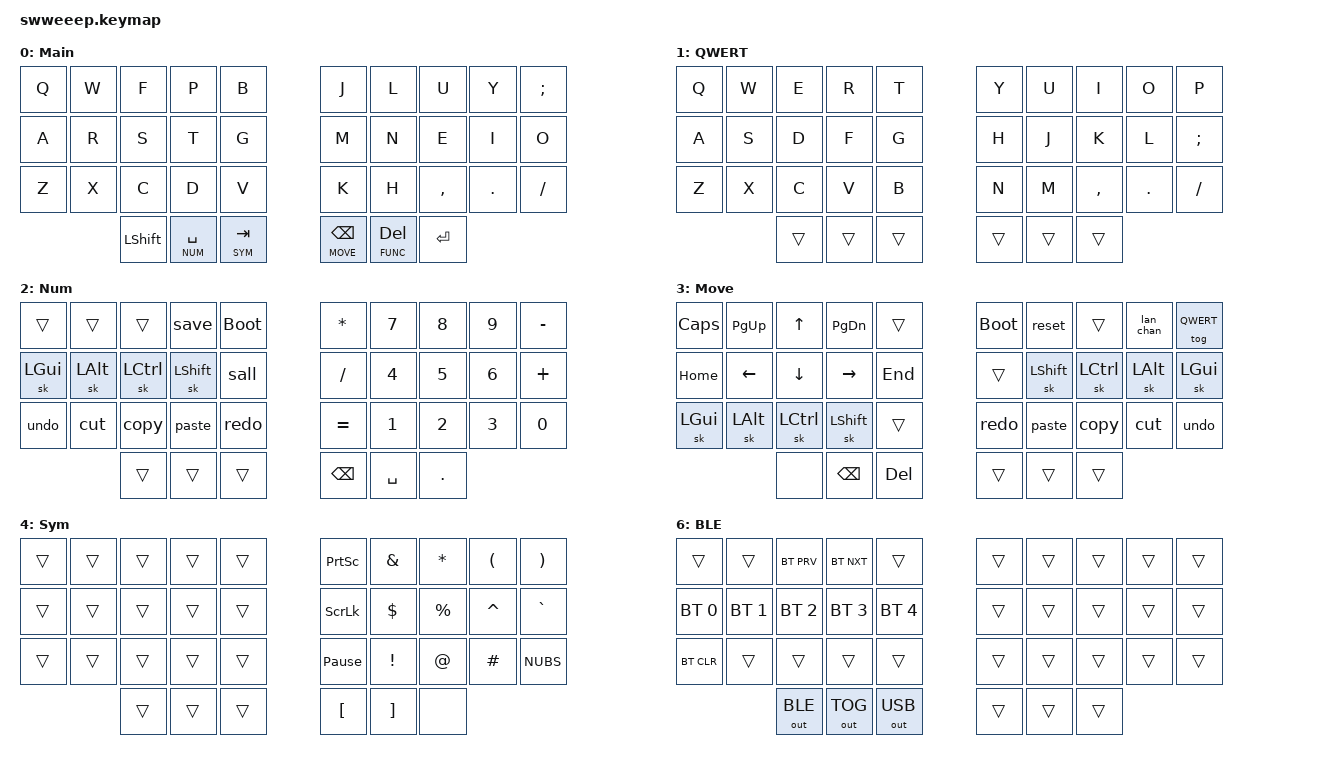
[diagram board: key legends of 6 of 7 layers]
#include <behaviors.dtsi>
#include <dt-bindings/zmk/keys.h>
#include <dt-bindings/zmk/bt.h>
#include <dt-bindings/zmk/outputs.h>

#define MAIN  0
#define QWERT 1
#define NUM   2
#define MOVE  3
#define SYM   4
#define FUNC  5
#define BLE   6

&caps_word {
    continue-list = <UNDERSCORE MINUS>;
};

/ {
    combos {
        compatible = "zmk,combos";
        combo_undo {
            timeout-ms = <50>;
            key-positions = <20 21>;
            bindings = <&kp LC(Z)>;
        };
        combo_q {
            timeout-ms = <50>;
            key-positions = <21 22>;
            bindings = <&kp Q>;
        };
        combo_semicolon {
            timeout-ms = <50>;
            key-positions = <27 28>;
            bindings = <&kp SEMI>;
        };
    };
};

/ {

    behaviors {
        hm: homerow_mods {
            compatible = "zmk,behavior-hold-tap";
            label = "HOMEROW_MODS";
            #binding-cells = <2>;
            tapping-term-ms = <200>;
            quick_tap_ms = <0>;
            flavor = "balanced";
            bindings = <&kp>, <&kp>;
        };
        hs: homerow_shift {
            compatible = "zmk,behavior-hold-tap";
            label = "HOMEROW_SHIFT";
            #binding-cells = <2>;
            tapping-term-ms = <175>;
            quick_tap_ms = <0>;
            flavor = "balanced";
            bindings = <&kp>, <&kp>;
        };
    };

    keymap {
        compatible = "zmk,keymap";

        main_layer {
            label = "Main";

            bindings = <
    &kp Q        &kp W        &kp F       &kp P         &kp B                                       &kp J         &kp L        &kp U         &kp Y       &kp SEMI
    &kp A        &kp R        &kp S       &kp T         &kp G                                       &kp M         &kp N        &kp E         &kp I       &kp O
    &kp Z        &kp X        &kp C       &kp D         &kp V                                       &kp K         &kp H        &kp COMMA     &kp DOT     &kp FSLH
                              &kp LSHFT   &lt NUM SPACE &lt SYM TAB                             &lt MOVE BSPC   &lt FUNC DEL  &kp RET
            >;
        };

        qwert_layer {
            label = "QWERT";

            bindings = <
    &kp Q        &kp W        &kp E       &kp R         &kp T                                   &kp Y         &kp U        &kp I         &kp O       &kp P
    &kp A        &kp S        &kp D       &kp F         &kp G                                   &kp H         &kp J        &kp K         &kp L       &kp SEMI
    &kp Z        &kp X        &kp C       &kp V         &kp B                                   &kp N         &kp M        &kp COMMA     &kp DOT     &kp FSLH
                              &trans      &trans        &trans                                  &trans        &trans       &trans
            >;
        };

        num_layer {
            label = "Num";

            bindings = <
    &trans       &trans       &trans      &save         &bootloader                             &kp ASTRK     &kp N7       &kp N8        &kp N9      &kp MINUS
    &sk LGUI     &sk LALT     &sk LCTRL   &sk LSHFT     &sall                                   &kp FSLH      &kp N4       &kp N5        &kp N6      &kp PLUS
    &undo        &cut         &copy       &paste        &redo                                   &kp EQUAL     &kp N1       &kp N2        &kp N3      &kp N0
                              &trans        &trans      &trans                                  &kp BSPC      &kp SPACE    &kp DOT
            >;
        };

        move_layer {
            label = "Move";

            bindings = <
    &kp CAPS     &kp PG_UP    &kp UP      &kp PG_DN     &trans                                   &bootloader   &reset       &trans        &lan_chan   &tog QWERT
    &kp HOME     &kp LEFT     &kp DOWN    &kp RIGHT     &kp END                                  &trans        &sk LSHIFT   &sk LCTRL     &sk LALT    &sk LGUI
    &sk LGUI     &sk LALT     &sk LCTRL    &sk LSHFT     &trans                                  &redo         &paste       &copy         &cut        &undo
                              &none       &kp BSPC      &kp DEL                                  &trans        &trans       &trans
            >;
        };

        sym_layer {
            label = "Sym";

            bindings = <
    &trans      &trans      &trans      &trans      &trans                                       &kp PSCRN   &kp AMPS    &kp ASTRK   &kp LPAR    &kp RPAR
    &trans      &trans      &trans      &trans      &trans                                       &kp SLCK    &kp DLLR    &kp PRCNT   &kp CARET   &kp GRAVE
    &trans      &trans      &trans      &trans      &trans                                 &kp PAUSE_BREAK   &kp EXCL    &kp AT      &kp HASH    &kp NUBS
                            &trans      &trans      &trans                                       &kp LBKT    &kp RBKT    &none
            >;
        };

        func_layer {
            label = "Func";

            bindings = <
    &kp F9     &kp F10    &kp F11   &kp F12    &kp K_VOL_UP                                      &trans   &kp LANG1    &trans        &trans      &trans
    &kp F5     &kp F6     &kp F7    &kp F8     &kp C_MUTE                                        &trans   &sk LSHF T   &sk LCTRL     &sk LALT    &sk LGUI
    &sk F1     &sk F2     &sk F3    &sk F4     &kp K_VOL_DN                                      &redo    &paste       &copy         &cut        &undo
                              &none      &none      &none                                        &trans   &trans       &trans
            >;
        };

        ble_layer {
            label = "BLE";

            bindings = <
    &trans       &trans       &bt BT_PRV   &bt BT_NXT    &trans                                  &trans      &trans      &trans      &trans      &trans
    &bt BT_SEL 0 &bt BT_SEL 1 &bt BT_SEL 2 &bt BT_SEL 3  &bt BT_SEL 4                            &trans      &trans      &trans      &trans      &trans
    &bt BT_CLR   &trans       &trans       &trans        &trans                                  &trans      &trans      &trans      &trans      &trans
                                           &out OUT_BLE  &out OUT_TOG  &out OUT_USB              &trans      &trans      &trans
            >;
        };
    };
};
